AUTOSAR XML (schema 00047)
package /Components
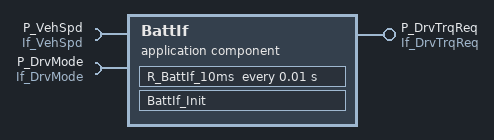
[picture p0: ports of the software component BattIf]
  application sw component type BattIf
    require port P_VehSpd: nonqueued-receiver-com-spec{data-element=In_VehSpd, init-value=0}, required-interface=If_VehSpd
    require port P_DrvMode: nonqueued-receiver-com-spec{data-element=In_DrvMode, init-value=ECO}, required-interface=If_DrvMode
    provide port P_DrvTrqReq: nonqueued-sender-com-spec{data-element=Out_DrvTrqReq, init-value=0}, provided-interface=If_DrvTrqReq
    behavior BattIf_IB: handle-termination-and-restart=NO-SUPPORT, supports-multiple-instantiation=true
      ar-typed-per-instance-memorys:
        data BattIf_Irv_TrqLim: category=VALUE, sw-calibration-access=READ-ONLY, type=Float
        data Meas_TrqOut: category=VALUE, sw-calibration-access=READ-ONLY, type=Float
      timing event Event_R_BattIf_10ms: start-on-event=R_BattIf_10ms, period=0.01
      runnable BattIf_Init
      runnable R_BattIf_10ms: symbol=BattIf_Step
        data-write-access:
          access OUT_P_DrvTrqReq_Out_DrvTrqReq: accessed-variable=P_DrvTrqReq.Out_DrvTrqReq
        parameter access SCALPRM_Cal_TrqMax: accessed-parameter=Cal_TrqMax
      shared-parameters:
        parameter data prototype Cal_TrqMax: category=VALUE, sw-calibration-access=READ-WRITE, type=Float, init-value=constant-reference={short-label=Cal_TrqMax, constant=Cal_TrqMax}
